# CY8C5568AXI_060 register map
File version: 0.1
CY8C55
Registers are 8-bit, read-write, no defined reset value unless marked. A register's access mark holds for its fields unless they carry their own. Offsets are from the block's base; lines under a group give offsets from that group; [hi:lo] are bit positions; {n}, {i} and the like mark numbered series; 'fields as' and 'values as' point back to an identical list; <NAME> marks a mode.

## Memory map
0x400043A1 TIA_PulseIn size 0x17B6
0x400043A4 Opamp_PulseRef size 0x179E
0x400043A5 USBUART_1 size 0x1CF9 — USBFS
0x400043A6 Filter_PulseInBand size 0x840F
0x400043A7 CapSense_1_CompCH0 size 0x17EA
0x400043A8 CapSense_1_IdacCH0 size 0x17DC
0x400043A8 VDAC_PulseRef size 0x17DA
0x400043A8 IDAC8_PulseIR size 0x17DB
0x400043A8 IDAC8_PulseRed size 0x17D9
0x400043AA ADC_PulseIn size 0x17E0
0x40004614 ADC_SAR_ProxIR size 0x158D — SAR ADC
0x40006407 PWM_PulseLEDs size 0x17F
0x40006408 PrISM_LEDCool size 0x41 — PrISM
0x40006423 UART_Debug size 0x144 — UART
0x40006440 UART_Net size 0x10A — UART
0x4000647C CapSense_1 size 0x20
0x40006508 PrISM_LEDWarm size 0x41 — PrISM
0x4000650B PrISM_LEDBlue size 0x41 — PrISM

## PrISM_LEDCool — PrISM
Base 0x40006408
Same registers: PrISM_LEDWarm 0x40006508, PrISM_LEDBlue 0x4000650B
0x00 PrISM_SEED — Current seed value
0x10 PrISM_POLYNOM — Polynomial
0x20 PrISM_DENSITY0 — Pulse Density 0
0x30 PrISM_DENSITY1 — Pulse Density 1
0x40 PrISM_SEED_COPY — Start seed value

## PWM_PulseLEDs
Base 0x40006407
0x00 PWM_PulseLEDs_DeadBand_Counter — UDB DeadBand - DeadBand Counter Value
0x1F PWM_PulseLEDs__COMPARE1 — UDB.D0 - Assigned Compare1 Value
0x20 PWM_PulseLEDs_DeadBand_Count — UDB DeadBand - Assigned DeadBand Count Value
0x2F PWM_PulseLEDs__COMPARE2 — UDB.D1 - Assigned Compare2 Value
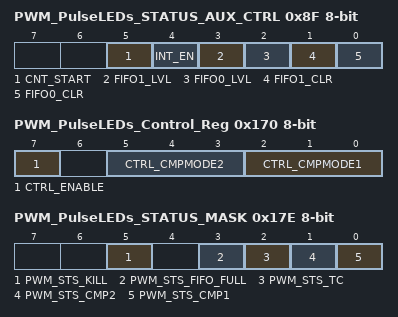
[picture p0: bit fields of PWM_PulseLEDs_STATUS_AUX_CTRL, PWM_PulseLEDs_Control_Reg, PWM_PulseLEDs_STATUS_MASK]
0x8F PWM_PulseLEDs_STATUS_AUX_CTRL — UDB Auxilliary Control Register
  [5] CNT_START — FIFO0 clear
    0=E_CNT_START0 (Disable counter); 1=E_CNT_START1 (Enable counter)
  [4] INT_EN
    0=E_INT_EN0 (Interrupt disabled); 1=E_INT_EN1 (Interrupt enabled)
  [3] FIFO1_LVL — FIFO level
    0=E_FIFO_LVL_0 (FIFO LVL: input mode: FIFO not full; output mode: FIFO not empty); 1=E_FIFO_LVL_1 (FIFO LVL: input mode: FIFO at least 1/2 empty; output mode: FIFO at least 1/2 full)
  [2] FIFO0_LVL — FIFO level
    values as FIFO1_LVL
  [1] FIFO1_CLR — FIFO1 clear
    0=E_FIFO_CLR_0 (Normal FIFO operation); 1=E_FIFO_CLR_1 (Clear FIFO state)
  [0] FIFO0_CLR — FIFO0 clear
    values as FIFO1_CLR
0x170 PWM_PulseLEDs_Control_Reg — UDB Control Register - Assigned Control Register Value
  [7] CTRL_ENABLE — Enable the PWM
  [5:3] CTRL_CMPMODE2 — Compare mode 2
  [2:0] CTRL_CMPMODE1 — Compare mode 1
0x17E PWM_PulseLEDs_STATUS_MASK — UDB Status bits Interrupt Mask Enable Register
  [5] PWM_STS_KILL ro — Enables the Interrupt on Kill
  [3] PWM_STS_FIFO_FULL ro — FIFO Full Status Mask
  [2] PWM_STS_TC ro — Enables the Interrupt on Terminal Count
  [1] PWM_STS_CMP2 ro — Enables the Interrupt on Compare 2
  [0] PWM_STS_CMP1 ro — Enables the Interrupt on Compare 1

## USBUART_1 — USBFS
Base 0x400043A5
0x00 USBUART_1_PM_ACT_CFG — Active Power Mode Configuration Register
0x10 USBUART_1_PM_STBY_CFG — Standby Power Mode Configuration Register
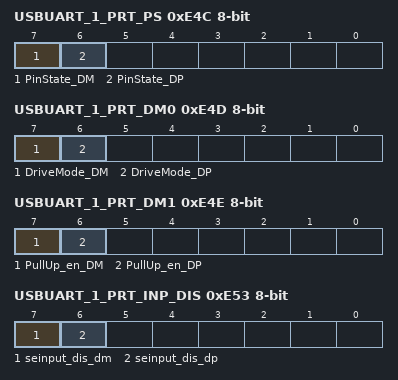
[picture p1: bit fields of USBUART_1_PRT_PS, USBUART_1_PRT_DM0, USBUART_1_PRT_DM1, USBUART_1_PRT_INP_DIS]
0xE4C USBUART_1_PRT_PS — Port Pin State Register
  [7] PinState_DM ro, [6] PinState_DP ro
0xE4D USBUART_1_PRT_DM0 — Port Drive Mode Register
  [7] DriveMode_DM, [6] DriveMode_DP
0xE4E USBUART_1_PRT_DM1 — Port Drive Mode Register
  [7] PullUp_en_DM, [6] PullUp_en_DP
0xE53 USBUART_1_PRT_INP_DIS — Input buffer disable override
  [7] seinput_dis_dm, [6] seinput_dis_dp
0x1C5B USBUART_1_EP0_DR0 — bmRequestType
0x1C5C USBUART_1_EP0_DR1 — bRequest
0x1C5D USBUART_1_EP0_DR2 — wValueLo
0x1C5E USBUART_1_EP0_DR3 — wValueHi
0x1C5F USBUART_1_EP0_DR4 — wIndexLo
0x1C60 USBUART_1_EP0_DR5 — wIndexHi
0x1C61 USBUART_1_EP0_DR6 — lengthLo
0x1C62 USBUART_1_EP0_DR7 — lengthHi
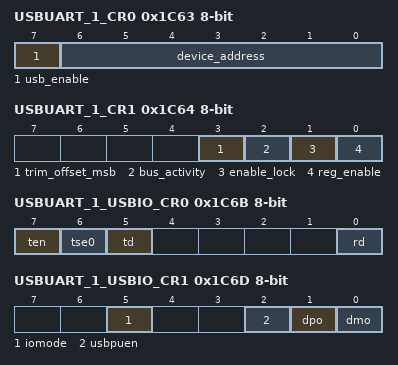
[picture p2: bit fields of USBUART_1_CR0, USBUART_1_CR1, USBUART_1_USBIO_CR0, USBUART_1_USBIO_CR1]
0x1C63 USBUART_1_CR0 — USB Control Register 0
  [7] usb_enable, [6:0] device_address ro
0x1C64 USBUART_1_CR1 — USB Control Register 1
  [3] trim_offset_msb, [2] bus_activity, [1] enable_lock, [0] reg_enable
{0x1C59+0x10*i} USBUART_1_SIE_EP{i}_CR0 (i=1..8) — The Endpoint{i} Control Register
0x1C6B USBUART_1_USBIO_CR0 — USBIO Control Register 0
  [7] ten, [6] tse0, [5] td, [0] rd ro
0x1C6D USBUART_1_USBIO_CR1 — USBIO Control Register 1
  [5] iomode, [2] usbpuen, [1] dpo ro, [0] dmo ro
0x1CE7 USBUART_1_BUF_SIZE — Dedicated Endpoint Buffer Size Register
0x1CE9 USBUART_1_EP_ACTIVE — Endpoint Active Indication Register
0x1CEA USBUART_1_EP_TYPE — Endpoint Type (IN/OUT) Indication
0x1CF8 USBUART_1_USB_CLK_EN — USB Block Clock Enable Register
